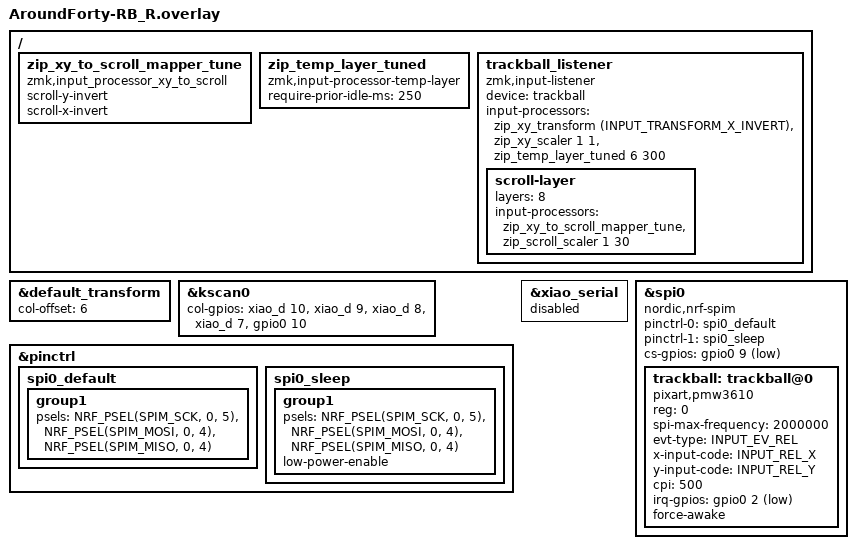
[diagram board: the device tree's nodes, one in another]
#include "AroundForty-RB.dtsi"
#include <dt-bindings/zmk/pointing.h>
#include <dt-bindings/zmk/input_transform.h>
#include <input/processors.dtsi>
#include <zephyr/dt-bindings/input/input-event-codes.h>

&default_transform {
    col-offset = <6>;
};

&kscan0 {
    col-gpios
        = <&xiao_d 10 GPIO_ACTIVE_HIGH>
        , <&xiao_d  9 GPIO_ACTIVE_HIGH>
        , <&xiao_d  8 GPIO_ACTIVE_HIGH>
        , <&xiao_d  7 GPIO_ACTIVE_HIGH>
        , <&gpio0  10 GPIO_ACTIVE_HIGH>
        ;
};


/ {
    /* スクロール方向をいつでも反転できるようにするための設定 */
    zip_xy_to_scroll_mapper_tune: zip_xy_to_scroll_mapper_tune {
        compatible = "zmk,input_processor_xy_to_scroll";
        #input-processor-cells = <0>;
        scroll-y-invert;
        scroll-x-invert;
    };

    /* 【追加】AMLの誤爆を防ぐカスタムプロセッサを定義 */
    zip_temp_layer_tuned: zip_temp_layer_tuned {
        compatible = "zmk,input-processor-temp-layer";
        #input-processor-cells = <2>;
        /* キー入力後、指定した時間(ミリ秒)はAMLを起動しない */
        require-prior-idle-ms = <250>; 
    };

    trackball_listener: trackball_listener {
        compatible = "zmk,input-listener";
        device = <&trackball>;
        input-processors = <&zip_xy_transform (INPUT_TRANSFORM_X_INVERT)>,
                           <&zip_xy_scaler 1 1>,
                           <&zip_temp_layer_tuned 6 300>;
        scroll-layer {
            layers = <8>;
            input-processors = <&zip_xy_to_scroll_mapper_tune>,
                               <&zip_scroll_scaler 1 30>;
        };
    };
};

&pinctrl {
    spi0_default: spi0_default {
        group1 {
            psels = <NRF_PSEL(SPIM_SCK,  0, 5)>,
                    <NRF_PSEL(SPIM_MOSI, 0, 4)>,
                    <NRF_PSEL(SPIM_MISO, 0, 4)>;
        };
    };

    spi0_sleep: spi0_sleep {
        group1 {
            psels = <NRF_PSEL(SPIM_SCK,  0, 5)>,
                    <NRF_PSEL(SPIM_MOSI, 0, 4)>,
                    <NRF_PSEL(SPIM_MISO, 0, 4)>;
            low-power-enable;
        };
    };
};

&xiao_serial { status = "disabled"; };

&spi0 {
    status = "okay";
    compatible = "nordic,nrf-spim";
    pinctrl-0 = <&spi0_default>;
    pinctrl-1 = <&spi0_sleep>;
    pinctrl-names = "default", "sleep";
    cs-gpios = <&gpio0 9 GPIO_ACTIVE_LOW>;

    trackball: trackball@0 {
        status = "okay";
        compatible = "pixart,pmw3610";
        reg = <0>;
        spi-max-frequency = <2000000>;
        evt-type = <INPUT_EV_REL>;
        x-input-code = <INPUT_REL_X>;
        y-input-code = <INPUT_REL_Y>;
        cpi = <500>;
        irq-gpios = <&gpio0 2 (GPIO_ACTIVE_LOW | GPIO_PULL_UP)>;
        force-awake;
    };
};
